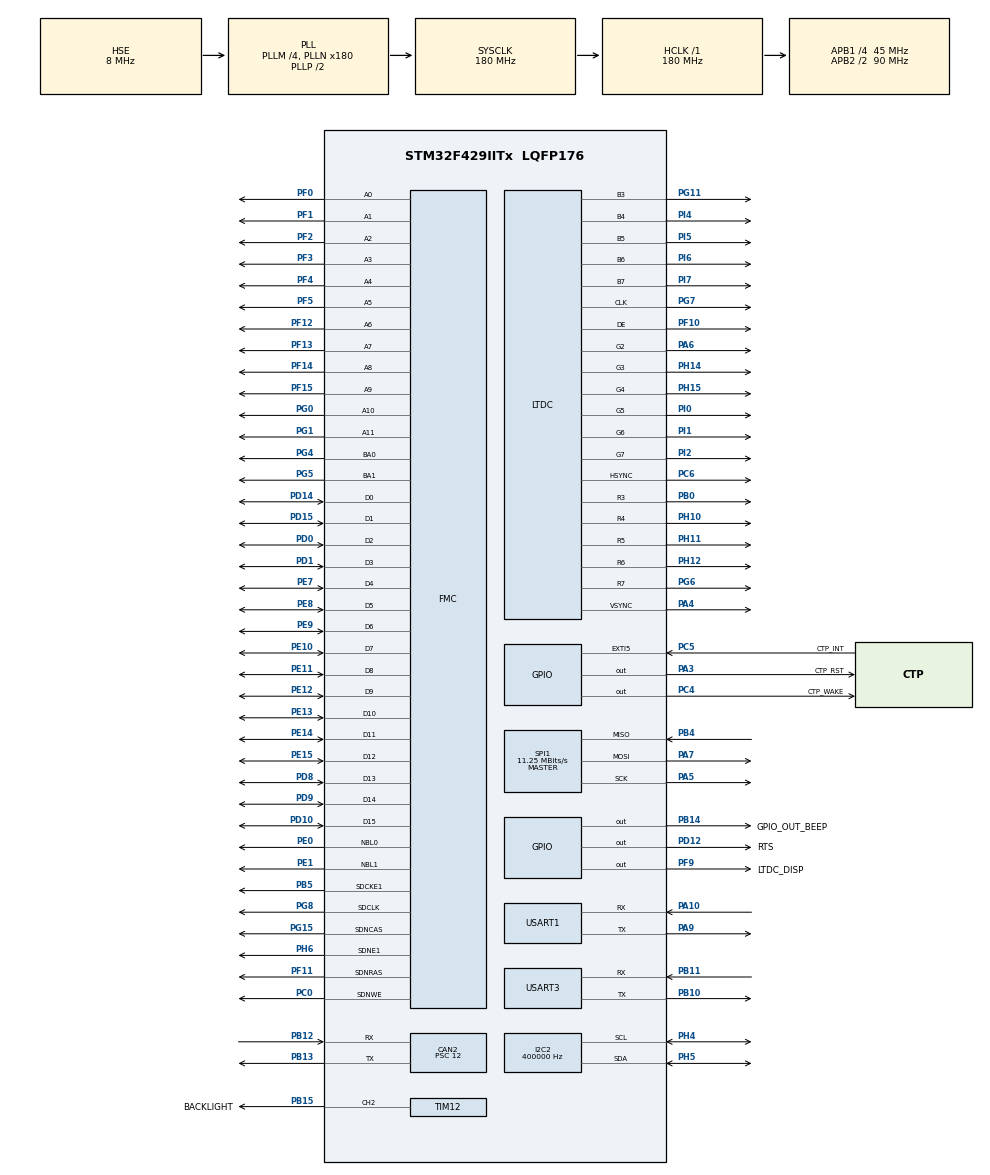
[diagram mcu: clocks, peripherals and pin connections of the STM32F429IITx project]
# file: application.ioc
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CAN2.ABOM=ENABLE
CAN2.BS1=CAN_BS1_12TQ
CAN2.BS2=CAN_BS2_2TQ
CAN2.CalculateBaudRate=250000
CAN2.CalculateTimeBit=3999.99
CAN2.CalculateTimeQuantum=266.66666666666663
CAN2.NART=ENABLE
CAN2.Prescaler=12
DMA2D.ColorMode=DMA2D_OUTPUT_RGB565
Dma.Request0=SPI1_RX
Dma.Request1=SPI1_TX
Dma.SPI1_RX.0.Direction=DMA_PERIPH_TO_MEMORY
Dma.SPI1_RX.0.FIFOMode=DMA_FIFOMODE_DISABLE
Dma.SPI1_RX.0.Instance=DMA2_Stream0
Dma.SPI1_RX.0.MemDataAlignment=DMA_MDATAALIGN_BYTE
Dma.SPI1_RX.0.MemInc=DMA_MINC_ENABLE
Dma.SPI1_RX.0.Mode=DMA_NORMAL
Dma.SPI1_RX.0.PeriphDataAlignment=DMA_PDATAALIGN_BYTE
Dma.SPI1_RX.0.PeriphInc=DMA_PINC_DISABLE
Dma.SPI1_RX.0.Priority=DMA_PRIORITY_LOW
Dma.SPI1_TX.1.Direction=DMA_MEMORY_TO_PERIPH
Dma.SPI1_TX.1.FIFOMode=DMA_FIFOMODE_DISABLE
Dma.SPI1_TX.1.Instance=DMA2_Stream3
Dma.SPI1_TX.1.MemDataAlignment=DMA_MDATAALIGN_BYTE
Dma.SPI1_TX.1.MemInc=DMA_MINC_ENABLE
Dma.SPI1_TX.1.Mode=DMA_NORMAL
Dma.SPI1_TX.1.PeriphDataAlignment=DMA_PDATAALIGN_BYTE
Dma.SPI1_TX.1.PeriphInc=DMA_PINC_DISABLE
Dma.SPI1_TX.1.Priority=DMA_PRIORITY_LOW
FMC.CASLatency2=FMC_SDRAM_CAS_LATENCY_3
FMC.ExitSelfRefreshDelay2=7
FMC.LoadToActiveDelay2=2
FMC.RCDDelay2=2
FMC.RPDelay1=2
FMC.RPDelay2=2
FMC.ReadBurst1=FMC_SDRAM_RBURST_ENABLE
FMC.ReadBurst2=FMC_SDRAM_RBURST_ENABLE
FMC.RowCycleDelay1=7
FMC.RowCycleDelay2=7
FMC.SDClockPeriod1=FMC_SDRAM_CLOCK_PERIOD_2
FMC.SDClockPeriod2=FMC_SDRAM_CLOCK_PERIOD_2
FMC.SelfRefreshTime2=4
FMC.WriteRecoveryTime2=3
FREERTOS.BinarySemaphores01=ModbusTaskBinarySem,Dynamic,NULL
FREERTOS.INCLUDE_uxTaskGetStackHighWaterMark=1
FREERTOS.INCLUDE_vTaskDelayUntil=1
FREERTOS.INCLUDE_xQueueGetMutexHolder=1
FREERTOS.Queues01=ObjectValueQueue,20,ReceiverData_t,0,Dynamic,NULL,NULL
FREERTOS.Tasks01=defaultTask,24,4096,StartDefaultTask,Default,NULL,Dynamic,NULL,NULL;ModbusRTUTask,24,512,StartModbusRTUTask,Default,NULL,Dynamic,NULL,NULL
FREERTOS.configTOTAL_HEAP_SIZE=40960
FREERTOS.configUSE_APPLICATION_TASK_TAG=1
FREERTOS.configUSE_DAEMON_TASK_STARTUP_HOOK=0
FREERTOS.configUSE_IDLE_HOOK=1
FREERTOS.configUSE_TICK_HOOK=1
I2C2.ClockSpeed=400000
I2C2.I2C_Mode=I2C_Fast
LTDC.ActiveW=800
LTDC.Alpha_L0=255
LTDC.FBStartAdress_L0=0xd0500000
LTDC.HFP=48
LTDC.ImageHeight_L0=480
LTDC.ImageWidth_L0=800
LTDC.Layers=0
LTDC.PixelFormat_L0=LTDC_PIXEL_FORMAT_RGB565
LTDC.VBP=12
LTDC.VFP=12
LTDC.VSync=8
LTDC.WindowX1_L0=800
LTDC.WindowY1_L0=480
Mcu.Family=STM32F4
Mcu.Name=STM32F429IITx
Mcu.Package=LQFP176
NVIC.CAN2_RX0_IRQn=true\:5\:0\:false\:false\:true\:true\:true\:true
NVIC.CAN2_RX1_IRQn=true\:5\:0\:false\:false\:true\:true\:true\:true
NVIC.DMA2D_IRQn=true\:5\:0\:true\:false\:true\:true\:true\:true
NVIC.DMA2_Stream0_IRQn=true\:5\:0\:false\:false\:true\:true\:false\:true
NVIC.DMA2_Stream3_IRQn=true\:5\:0\:false\:false\:true\:true\:false\:true
NVIC.I2C2_ER_IRQn=true\:5\:0\:false\:false\:true\:true\:true\:true
NVIC.I2C2_EV_IRQn=true\:5\:0\:false\:false\:true\:true\:true\:true
NVIC.LTDC_ER_IRQn=true\:5\:0\:true\:false\:true\:true\:true\:true
NVIC.LTDC_IRQn=true\:5\:0\:true\:false\:true\:true\:true\:true
NVIC.PriorityGroup=NVIC_PRIORITYGROUP_4
NVIC.TIM5_IRQn=true\:0\:0\:false\:false\:true\:false\:false\:true
NVIC.TIM7_IRQn=true\:5\:0\:false\:false\:true\:true\:true\:true
NVIC.TimeBase=TIM5_IRQn
NVIC.TimeBaseIP=TIM5
NVIC.USART1_IRQn=true\:5\:0\:false\:false\:true\:true\:true\:true
NVIC.USART3_IRQn=true\:5\:0\:false\:false\:true\:true\:true\:true
PA10.Mode=Asynchronous
PA10.Signal=USART1_RX
PA13.Mode=Serial_Wire
PA13.Signal=SYS_JTMS-SWDIO
PA14.Mode=Serial_Wire
PA14.Signal=SYS_JTCK-SWCLK
PA3.GPIO_Label=CTP_RST
PA3.Signal=GPIO_Output
PA4.Mode=RGB565
PA4.Signal=LTDC_VSYNC
PA5.Mode=Full_Duplex_Master
PA5.Signal=SPI1_SCK
PA6.Mode=RGB565
PA6.Signal=LTDC_G2
PA7.Mode=Full_Duplex_Master
PA7.Signal=SPI1_MOSI
PA9.Mode=Asynchronous
PA9.Signal=USART1_TX
PB0.Mode=RGB565
PB0.Signal=LTDC_R3
PB10.Mode=Asynchronous
PB10.Signal=USART3_TX
PB11.Mode=Asynchronous
PB11.Signal=USART3_RX
PB12.Mode=CAN_Activate
PB12.Signal=CAN2_RX
PB13.Mode=CAN_Activate
PB13.Signal=CAN2_TX
PB14.GPIO_Label=GPIO_OUT_BEEP
PB14.Signal=GPIO_Output
PB15.GPIO_Label=BACKLIGHT
PB15.Signal=S_TIM12_CH2
PB4.Mode=Full_Duplex_Master
PB4.Signal=SPI1_MISO
PB5.Mode=SdramChipSelect2_2
PB5.Signal=FMC_SDCKE1
PC0.Signal=FMC_SDNWE
PC14/OSC32_IN.Mode=LSE-External-Oscillator
PC14/OSC32_IN.Signal=RCC_OSC32_IN
PC15/OSC32_OUT.Mode=LSE-External-Oscillator
PC15/OSC32_OUT.Signal=RCC_OSC32_OUT
PC4.GPIO_Label=CTP_WAKE
PC4.Signal=GPIO_Output
PC5.GPIO_Label=CTP_INT
PC5.Signal=GPXTI5
PC6.Mode=RGB565
PC6.Signal=LTDC_HSYNC
PD0.Signal=FMC_D2_DA2
PD1.Signal=FMC_D3_DA3
PD10.Signal=FMC_D15_DA15
PD12.GPIO_Label=RTS
PD12.Signal=GPIO_Output
PD14.Signal=FMC_D0_DA0
PD15.Signal=FMC_D1_DA1
PD8.Signal=FMC_D13_DA13
PD9.Signal=FMC_D14_DA14
PE0.Signal=FMC_NBL0
PE1.Signal=FMC_NBL1
PE10.Signal=FMC_D7_DA7
PE11.Signal=FMC_D8_DA8
PE12.Signal=FMC_D9_DA9
PE13.Signal=FMC_D10_DA10
PE14.Signal=FMC_D11_DA11
PE15.Signal=FMC_D12_DA12
PE4.Signal=LTDC_B0
PE5.Signal=LTDC_G0
PE6.Signal=LTDC_G1
PE7.Signal=FMC_D4_DA4
PE8.Signal=FMC_D5_DA5
PE9.Signal=FMC_D6_DA6
PF0.Signal=FMC_A0
PF1.Signal=FMC_A1
PF10.Mode=RGB565
PF10.Signal=LTDC_DE
PF11.Signal=FMC_SDNRAS
PF12.Signal=FMC_A6
PF13.Signal=FMC_A7
PF14.Signal=FMC_A8
PF15.Signal=FMC_A9
PF2.Signal=FMC_A2
PF3.Signal=FMC_A3
PF4.Signal=FMC_A4
PF5.Signal=FMC_A5
PF9.GPIO_Label=LTDC_DISP
PF9.Signal=GPIO_Output
PG0.Signal=FMC_A10
PG1.Signal=FMC_A11
PG10.Signal=LTDC_B2
PG11.Mode=RGB565
PG11.Signal=LTDC_B3
PG12.Signal=LTDC_B1
PG15.Signal=FMC_SDNCAS
PG4.Signal=FMC_A14_BA0
PG5.Signal=FMC_A15_BA1
PG6.Mode=RGB565
PG6.Signal=LTDC_R7
PG7.Mode=RGB565
PG7.Signal=LTDC_CLK
PG8.Signal=FMC_SDCLK
PH0/OSC_IN.Mode=HSE-External-Oscillator
PH0/OSC_IN.Signal=RCC_OSC_IN
PH1/OSC_OUT.Mode=HSE-External-Oscillator
PH1/OSC_OUT.Signal=RCC_OSC_OUT
PH10.Mode=RGB565
PH10.Signal=LTDC_R4
PH11.Mode=RGB565
PH11.Signal=LTDC_R5
PH12.Mode=RGB565
PH12.Signal=LTDC_R6
PH14.Mode=RGB565
PH14.Signal=LTDC_G3
PH15.Mode=RGB565
PH15.Signal=LTDC_G4
PH4.Mode=I2C
PH4.Signal=I2C2_SCL
PH5.Mode=I2C
PH5.Signal=I2C2_SDA
PH6.Mode=SdramChipSelect2_2
PH6.Signal=FMC_SDNE1
PI0.Mode=RGB565
PI0.Signal=LTDC_G5
PI1.Mode=RGB565
PI1.Signal=LTDC_G6
PI2.Mode=RGB565
PI2.Signal=LTDC_G7
PI4.Mode=RGB565
PI4.Signal=LTDC_B4
PI5.Mode=RGB565
PI5.Signal=LTDC_B5
PI6.Mode=RGB565
PI6.Signal=LTDC_B6
PI7.Mode=RGB565
PI7.Signal=LTDC_B7
ProjectManager.HeapSize=0x1000
ProjectManager.StackSize=0x1000
ProjectManager.TargetToolchain=STM32CubeIDE
RCC.48MHZClocksFreq_Value=90000000
RCC.AHBFreq_Value=180000000
RCC.APB1CLKDivider=RCC_HCLK_DIV4
RCC.APB1Freq_Value=45000000
RCC.APB1TimFreq_Value=90000000
RCC.APB2CLKDivider=RCC_HCLK_DIV2
RCC.APB2Freq_Value=90000000
RCC.APB2TimFreq_Value=180000000
RCC.CortexFreq_Value=180000000
RCC.HCLKFreq_Value=180000000
RCC.HSE_VALUE=8000000
RCC.HSI_VALUE=16000000
RCC.LSE_Timout=1000
RCC.PLLM=4
RCC.PLLN=180
RCC.PLLSAIN=69
RCC.PLLSAIR=3
RCC.PLLSourceVirtual=RCC_PLLSOURCE_HSE
RCC.PWREXT_OverDrive=PWREXT_OverDrive_ACTIVATED
RCC.PWR_Regulator_Voltage_Scale=PWR_REGULATOR_VOLTAGE_SCALE1
RCC.RCC_RTC_Clock_Source=RCC_RTCCLKSOURCE_LSE
RCC.RCC_RTC_Clock_SourceVirtual=RCC_RTCCLKSOURCE_LSE
RCC.SYSCLKFreq_VALUE=180000000
RCC.SYSCLKSource=RCC_SYSCLKSOURCE_PLLCLK
RCC.VCOOutputFreq_Value=360000000
RTC.Format=RTC_FORMAT_BIN
RTC.Month=RTC_MONTH_JUNE
RTC.WeekDay=RTC_WEEKDAY_FRIDAY
RTC.Year=21
SH.FMC_A0.0=FMC_A0,12b-sda2
SH.FMC_A1.0=FMC_A1,12b-sda2
SH.FMC_A10.0=FMC_A10,12b-sda2
SH.FMC_A11.0=FMC_A11,12b-sda2
SH.FMC_A14_BA0.0=FMC_BA0,FourSdramBanks2
SH.FMC_A15_BA1.0=FMC_BA1,FourSdramBanks2
SH.FMC_A2.0=FMC_A2,12b-sda2
SH.FMC_A3.0=FMC_A3,12b-sda2
SH.FMC_A4.0=FMC_A4,12b-sda2
SH.FMC_A5.0=FMC_A5,12b-sda2
SH.FMC_A6.0=FMC_A6,12b-sda2
SH.FMC_A7.0=FMC_A7,12b-sda2
SH.FMC_A8.0=FMC_A8,12b-sda2
SH.FMC_A9.0=FMC_A9,12b-sda2
SH.FMC_D0_DA0.0=FMC_D0,sd-16b-d2
SH.FMC_D10_DA10.0=FMC_D10,sd-16b-d2
SH.FMC_D11_DA11.0=FMC_D11,sd-16b-d2
SH.FMC_D12_DA12.0=FMC_D12,sd-16b-d2
SH.FMC_D13_DA13.0=FMC_D13,sd-16b-d2
SH.FMC_D14_DA14.0=FMC_D14,sd-16b-d2
SH.FMC_D15_DA15.0=FMC_D15,sd-16b-d2
SH.FMC_D1_DA1.0=FMC_D1,sd-16b-d2
SH.FMC_D2_DA2.0=FMC_D2,sd-16b-d2
SH.FMC_D3_DA3.0=FMC_D3,sd-16b-d2
SH.FMC_D4_DA4.0=FMC_D4,sd-16b-d2
SH.FMC_D5_DA5.0=FMC_D5,sd-16b-d2
SH.FMC_D6_DA6.0=FMC_D6,sd-16b-d2
SH.FMC_D7_DA7.0=FMC_D7,sd-16b-d2
SH.FMC_D8_DA8.0=FMC_D8,sd-16b-d2
SH.FMC_D9_DA9.0=FMC_D9,sd-16b-d2
SH.FMC_NBL0.0=FMC_NBL0,Sd2ByteEnable2
SH.FMC_NBL1.0=FMC_NBL1,Sd2ByteEnable2
SH.FMC_SDCLK.0=FMC_SDCLK,12b-sda2
SH.FMC_SDNCAS.0=FMC_SDNCAS,12b-sda2
SH.FMC_SDNRAS.0=FMC_SDNRAS,12b-sda2
SH.FMC_SDNWE.0=FMC_SDNWE,12b-sda2
SH.S_TIM12_CH2.0=TIM12_CH2,PWM Generation2 CH2
SPI1.BaudRatePrescaler=SPI_BAUDRATEPRESCALER_8
SPI1.CalculateBaudRate=11.25 MBits/s
SPI1.Direction=SPI_DIRECTION_2LINES
SPI1.Mode=SPI_MODE_MASTER
SPI1.VirtualType=VM_MASTER
STMicroelectronics.X-CUBE-TOUCHGFX.4.16.1.ApplicationCcGraphicsJjApplication=TouchGFXOoGenerator
STMicroelectronics.X-CUBE-TOUCHGFX.4.16.1.tgfx_address1=0xd0500000
STMicroelectronics.X-CUBE-TOUCHGFX.4.16.1.tgfx_address2=0xd05bb800
STMicroelectronics.X-CUBE-TOUCHGFX.4.16.1.tgfx_buffering_strategy=Double
STMicroelectronics.X-CUBE-TOUCHGFX.4.16.1.tgfx_custom_height=480
STMicroelectronics.X-CUBE-TOUCHGFX.4.16.1.tgfx_display_interface=disp_ltdc
STMicroelectronics.X-CUBE-TOUCHGFX.4.16.1.tgfx_hardware_accelerator=dma_2d
STMicroelectronics.X-CUBE-TOUCHGFX.4.16.1.tgfx_location=By Address
STMicroelectronics.X-CUBE-TOUCHGFX.4.16.1.tgfx_vsync=vsync_ltdc
TIM10.Period=0
TIM12.Channel-PWM\ Generation2\ CH2=TIM_CHANNEL_2
TIM12.Period=99
TIM12.Prescaler=450-1
TIM7.Period=0
USART1.VirtualMode=VM_ASYNC
USART3.VirtualMode=VM_ASYNC
VP_CRC_VS_CRC.Mode=CRC_Activate
VP_DMA2D_VS_DMA2D.Mode=DMA2D_Activate
VP_FREERTOS_VS_CMSIS_V2.Mode=CMSIS_V2
VP_RTC_VS_RTC_Activate.Mode=RTC_Enabled
VP_RTC_VS_RTC_Calendar.Mode=RTC_Calendar
VP_STMicroelectronics.X-CUBE-TOUCHGFX_VS_GraphicsJjApplication_4.16.1.Mode=GraphicsJjApplication
VP_SYS_VS_tim5.Mode=TIM5
VP_TIM10_VS_ClockSourceINT.Mode=Enable_Timer
VP_TIM12_VS_ClockSourceINT.Mode=Internal
VP_TIM7_VS_ClockSourceINT.Mode=Enable_Timer
board=custom

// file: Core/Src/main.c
/* USER CODE BEGIN Header */
/**
  ******************************************************************************
  * @file           : main.c
  * @brief          : Main program body
  ******************************************************************************
  * @attention
  *
  * <h2><center>&copy; Copyright (c) 2022 STMicroelectronics.
  * All rights reserved.</center></h2>
  *
  * This software component is licensed by ST under Ultimate Liberty license
  * SLA0044, the "License"; You may not use this file except in compliance with
  * the License. You may obtain a copy of the License at:
  *                             www.st.com/SLA0044
  *
  ******************************************************************************
  */
/* USER CODE END Header */
#include "main.h"
#include "cmsis_os.h"
#include "app_touchgfx.h"

/* USER CODE BEGIN Includes */
#include <string.h>
#include <stdio.h>
#include "ExHardware.h"
#include "w25q128jv.h"
/* USER CODE END Includes */

CAN_HandleTypeDef hcan2;

CRC_HandleTypeDef hcrc;

DMA2D_HandleTypeDef hdma2d;

I2C_HandleTypeDef hi2c2;

LTDC_HandleTypeDef hltdc;

RTC_HandleTypeDef hrtc;

SPI_HandleTypeDef hspi1;
DMA_HandleTypeDef hdma_spi1_rx;
DMA_HandleTypeDef hdma_spi1_tx;

TIM_HandleTypeDef htim7;
TIM_HandleTypeDef htim10;
TIM_HandleTypeDef htim12;

UART_HandleTypeDef huart1;
UART_HandleTypeDef huart3;

SDRAM_HandleTypeDef hsdram2;

/* Definitions for defaultTask */
osThreadId_t defaultTaskHandle;
const osThreadAttr_t defaultTask_attributes = {
  .name = "defaultTask",
  .stack_size = 4096 * 4,
  .priority = (osPriority_t) osPriorityNormal,
};
/* Definitions for ModbusRTUTask */
osThreadId_t ModbusRTUTaskHandle;
const osThreadAttr_t ModbusRTUTask_attributes = {
  .name = "ModbusRTUTask",
  .stack_size = 512 * 4,
  .priority = (osPriority_t) osPriorityNormal,
};
/* Definitions for ObjectValueQueue */
osMessageQueueId_t ObjectValueQueueHandle;
const osMessageQueueAttr_t ObjectValueQueue_attributes = {
  .name = "ObjectValueQueue"
};
/* Definitions for ModbusTaskBinarySem */
osSemaphoreId_t ModbusTaskBinarySemHandle;
const osSemaphoreAttr_t ModbusTaskBinarySem_attributes = {
  .name = "ModbusTaskBinarySem"
};
/* USER CODE BEGIN PV */
uint8_t cacheBuf[ CACHE_SIZE ] __attribute__ ((section (".sdram.CatchBuffer")));
/* USER CODE END PV */

void SystemClock_Config(void);
static void MX_GPIO_Init(void);
static void MX_DMA_Init(void);
static void MX_CAN2_Init(void);
static void MX_LTDC_Init(void);
static void MX_FMC_Init(void);
static void MX_TIM7_Init(void);
static void MX_TIM10_Init(void);
static void MX_TIM12_Init(void);
static void MX_I2C2_Init(void);
static void MX_SPI1_Init(void);
static void MX_DMA2D_Init(void);
static void MX_USART1_UART_Init(void);
static void MX_USART3_UART_Init(void);
static void MX_CRC_Init(void);
static void MX_RTC_Init(void);
void StartDefaultTask(void *argument);
void StartModbusRTUTask(void *argument);

/* USER CODE BEGIN PFP */
void MX_SDRAM_InitEx ( void );
void ModbusRTUProcess ( void );
/* USER CODE END PFP */

int main(void)
{

  /* MCU Configuration--------------------------------------------------------*/

  /* Reset of all peripherals, Initializes the Flash interface and the Systick. */
  HAL_Init();

  /* Configure the system clock */
  SystemClock_Config();

  /* Initialize all configured peripherals */
  MX_GPIO_Init();
  MX_DMA_Init();
  MX_CAN2_Init();
  MX_LTDC_Init();
  MX_FMC_Init();
  MX_TIM7_Init();
  MX_TIM10_Init();
  MX_TIM12_Init();
  MX_I2C2_Init();
  MX_SPI1_Init();
  MX_DMA2D_Init();
  MX_USART1_UART_Init();
  MX_USART3_UART_Init();
  MX_CRC_Init();
  MX_RTC_Init();
  MX_TouchGFX_Init();
  /* USER CODE BEGIN 2 */
  *brightness = 100;
  Backlight_Control( BL_ON );
  /* USER CODE END 2 */

  /* Init scheduler */
  osKernelInitialize();

  /* Create the semaphores(s) */
  /* creation of ModbusTaskBinarySem */
  ModbusTaskBinarySemHandle = osSemaphoreNew(1, 1, &ModbusTaskBinarySem_attributes);

  /* Create the queue(s) */
  /* creation of ObjectValueQueue */
  ObjectValueQueueHandle = osMessageQueueNew (20, sizeof(ReceiverData_t), &ObjectValueQueue_attributes);

  /* Create the thread(s) */
  /* creation of defaultTask */
  defaultTaskHandle = osThreadNew(StartDefaultTask, NULL, &defaultTask_attributes);

  /* creation of ModbusRTUTask */
  ModbusRTUTaskHandle = osThreadNew(StartModbusRTUTask, NULL, &ModbusRTUTask_attributes);

  /* Start scheduler */
  osKernelStart();

  /* We should never get here as control is now taken by the scheduler */
  /* Infinite loop */
  while (1)
  {

  }
}

void SystemClock_Config(void)
{
	int CHECKLSI = 0;
  RCC_OscInitTypeDef RCC_OscInitStruct = {0};
  RCC_ClkInitTypeDef RCC_ClkInitStruct = {0};
  RCC_PeriphCLKInitTypeDef PeriphClkInitStruct = {0};

  /** Configure the main internal regulator output voltage
  */
  LSI:
  __HAL_RCC_PWR_CLK_ENABLE();
  __HAL_PWR_VOLTAGESCALING_CONFIG(PWR_REGULATOR_VOLTAGE_SCALE1);
  /** Initializes the RCC Oscillators according to the specified parameters
  * in the RCC_OscInitTypeDef structure.
  */
  if(CHECKLSI == 0)
  {
	  RCC_OscInitStruct.OscillatorType = RCC_OSCILLATORTYPE_HSE|RCC_OSCILLATORTYPE_LSE;
	  RCC_OscInitStruct.HSEState = RCC_HSE_ON;
	  RCC_OscInitStruct.LSEState = RCC_LSE_ON;
	  RCC_OscInitStruct.PLL.PLLState = RCC_PLL_ON;
	  RCC_OscInitStruct.PLL.PLLSource = RCC_PLLSOURCE_HSE;
	  RCC_OscInitStruct.PLL.PLLM = 4;
	  RCC_OscInitStruct.PLL.PLLN = 180;
	  RCC_OscInitStruct.PLL.PLLP = RCC_PLLP_DIV2;
	  RCC_OscInitStruct.PLL.PLLQ = 4;
  }
  else
  {
	  RCC_OscInitStruct.OscillatorType = RCC_OSCILLATORTYPE_LSI|RCC_OSCILLATORTYPE_HSE;
	  RCC_OscInitStruct.HSEState = RCC_HSE_ON;
	  RCC_OscInitStruct.LSIState =  RCC_LSI_ON;;
	  RCC_OscInitStruct.PLL.PLLState = RCC_PLL_ON;
	  RCC_OscInitStruct.PLL.PLLSource = RCC_PLLSOURCE_HSE;
	  RCC_OscInitStruct.PLL.PLLM = 4;
	  RCC_OscInitStruct.PLL.PLLN = 180;
	  RCC_OscInitStruct.PLL.PLLP = RCC_PLLP_DIV2;
	  RCC_OscInitStruct.PLL.PLLQ = 4;
  }

  if (HAL_RCC_OscConfig(&RCC_OscInitStruct) != HAL_OK)
  {
    CHECKLSI = 1;
    goto LSI;
    Error_Handler();
  }
  /** Activate the Over-Drive mode
  */
  if (HAL_PWREx_EnableOverDrive() != HAL_OK)
  {
    Error_Handler();
  }
  /** Initializes the CPU, AHB and APB buses clocks
  */
  RCC_ClkInitStruct.ClockType = RCC_CLOCKTYPE_HCLK|RCC_CLOCKTYPE_SYSCLK
                              |RCC_CLOCKTYPE_PCLK1|RCC_CLOCKTYPE_PCLK2;
  RCC_ClkInitStruct.SYSCLKSource = RCC_SYSCLKSOURCE_PLLCLK;
  RCC_ClkInitStruct.AHBCLKDivider = RCC_SYSCLK_DIV1;
  RCC_ClkInitStruct.APB1CLKDivider = RCC_HCLK_DIV4;
  RCC_ClkInitStruct.APB2CLKDivider = RCC_HCLK_DIV2;

  if (HAL_RCC_ClockConfig(&RCC_ClkInitStruct, FLASH_LATENCY_5) != HAL_OK)
  {
    Error_Handler();
  }
  PeriphClkInitStruct.PeriphClockSelection = RCC_PERIPHCLK_LTDC|RCC_PERIPHCLK_RTC;
  PeriphClkInitStruct.PLLSAI.PLLSAIN = 69;
  PeriphClkInitStruct.PLLSAI.PLLSAIR = 3;
  PeriphClkInitStruct.PLLSAIDivR = RCC_PLLSAIDIVR_2;
  if(CHECKLSI == 1)
	  PeriphClkInitStruct.RTCClockSelection = RCC_RTCCLKSOURCE_LSI;
  else
	  PeriphClkInitStruct.RTCClockSelection = RCC_RTCCLKSOURCE_LSE;
  if (HAL_RCCEx_PeriphCLKConfig(&PeriphClkInitStruct) != HAL_OK)
  {
	  goto LSI;
    Error_Handler();
  }
}

static void MX_CAN2_Init(void)
{

  hcan2.Instance = CAN2;
  hcan2.Init.Prescaler = 12;
  hcan2.Init.Mode = CAN_MODE_NORMAL;
  hcan2.Init.SyncJumpWidth = CAN_SJW_1TQ;
  hcan2.Init.TimeSeg1 = CAN_BS1_12TQ;
  hcan2.Init.TimeSeg2 = CAN_BS2_2TQ;
  hcan2.Init.TimeTriggeredMode = DISABLE;
  hcan2.Init.AutoBusOff = ENABLE;
  hcan2.Init.AutoWakeUp = DISABLE;
  hcan2.Init.AutoRetransmission = ENABLE;
  hcan2.Init.ReceiveFifoLocked = DISABLE;
  hcan2.Init.TransmitFifoPriority = DISABLE;
  if (HAL_CAN_Init(&hcan2) != HAL_OK)
  {
    Error_Handler();
  }
  /* USER CODE BEGIN CAN2_Init 2 */
  CAN_FilterTypeDef  sFilterConfig;

  /*##-2- Configure the CAN Filter ###########################################*/
  sFilterConfig.FilterBank = 14;
  sFilterConfig.FilterMode = CAN_FILTERMODE_IDMASK;
  sFilterConfig.FilterScale = CAN_FILTERSCALE_32BIT;
  sFilterConfig.FilterIdHigh = 0x0000;
  sFilterConfig.FilterIdLow = 0x0000;
  sFilterConfig.FilterMaskIdHigh = 0x0000;
  sFilterConfig.FilterMaskIdLow = 0x0000;
  sFilterConfig.FilterFIFOAssignment = CAN_RX_FIFO0;
  sFilterConfig.FilterActivation = ENABLE;
  sFilterConfig.SlaveStartFilterBank = 14;

  if ( HAL_CAN_ConfigFilter( &hcan2, &sFilterConfig ) != HAL_OK) {
	  return;
      /* Filter configuration Error */
      Error_Handler();
  }
  sFilterConfig.FilterFIFOAssignment = CAN_RX_FIFO1;

  if ( HAL_CAN_ConfigFilter( &hcan2, &sFilterConfig ) != HAL_OK) {
	  return;
      /* Filter configuration Error */
      Error_Handler();
  }

//  HAL_CAN_RegisterCallback(&hcan2, HAL_CAN_RX_FIFO0_MSG_PENDING_CB_ID, CustomCAN_RxFifoMsgPendingCallback );
//  HAL_CAN_RegisterCallback(&hcan2, HAL_CAN_RX_FIFO1_MSG_PENDING_CB_ID, CustomCAN_RxFifoMsgPendingCallback );

  /*##-3- Start the CAN peripheral ###########################################*/
  if( HAL_CAN_Start( &hcan2 ) != HAL_OK ) {
	  return;
      /* Start Error */
      Error_Handler( );
  }

  /*##-4- Activate CAN RX notification #######################################*/
  if( HAL_CAN_ActivateNotification( &hcan2, CAN_IT_RX_FIFO0_MSG_PENDING ) != HAL_OK) {
	  return;
      /* Notification Error */
      Error_Handler();
  }

  if( HAL_CAN_ActivateNotification( &hcan2, CAN_IT_RX_FIFO1_MSG_PENDING ) != HAL_OK) {
	  return;
	  /* Notification Error */
      Error_Handler();
  }

  if( HAL_CAN_ActivateNotification( &hcan2, CAN_IT_TX_MAILBOX_EMPTY	) != HAL_OK) {
      /* Notification Error */
      Error_Handler();
  }
  /* USER CODE END CAN2_Init 2 */

}

static void MX_CRC_Init(void)
{

  hcrc.Instance = CRC;
  if (HAL_CRC_Init(&hcrc) != HAL_OK)
  {
    Error_Handler();
  }

}

static void MX_DMA2D_Init(void)
{

  hdma2d.Instance = DMA2D;
  hdma2d.Init.Mode = DMA2D_M2M;
  hdma2d.Init.ColorMode = DMA2D_OUTPUT_RGB565;
  hdma2d.Init.OutputOffset = 0;
  hdma2d.LayerCfg[1].InputOffset = 0;
  hdma2d.LayerCfg[1].InputColorMode = DMA2D_INPUT_RGB565;
  hdma2d.LayerCfg[1].AlphaMode = DMA2D_NO_MODIF_ALPHA;
  hdma2d.LayerCfg[1].InputAlpha = 0;
  if (HAL_DMA2D_Init(&hdma2d) != HAL_OK)
  {
    Error_Handler();
  }
  if (HAL_DMA2D_ConfigLayer(&hdma2d, 1) != HAL_OK)
  {
    Error_Handler();
  }

}

static void MX_I2C2_Init(void)
{

  hi2c2.Instance = I2C2;
  hi2c2.Init.ClockSpeed = 400000;
  hi2c2.Init.DutyCycle = I2C_DUTYCYCLE_2;
  hi2c2.Init.OwnAddress1 = 0;
  hi2c2.Init.AddressingMode = I2C_ADDRESSINGMODE_7BIT;
  hi2c2.Init.DualAddressMode = I2C_DUALADDRESS_DISABLE;
  hi2c2.Init.OwnAddress2 = 0;
  hi2c2.Init.GeneralCallMode = I2C_GENERALCALL_DISABLE;
  hi2c2.Init.NoStretchMode = I2C_NOSTRETCH_DISABLE;
  if (HAL_I2C_Init(&hi2c2) != HAL_OK)
  {
    Error_Handler();
  }
  /** Configure Analogue filter
  */
  if (HAL_I2CEx_ConfigAnalogFilter(&hi2c2, I2C_ANALOGFILTER_ENABLE) != HAL_OK)
  {
    Error_Handler();
  }
  /** Configure Digital filter
  */
  if (HAL_I2CEx_ConfigDigitalFilter(&hi2c2, 0) != HAL_OK)
  {
    Error_Handler();
  }

}

static void MX_LTDC_Init(void)
{

  /* USER CODE BEGIN LTDC_Init 0 */
	hltdc.Instance = LTDC;
	HAL_LTDC_DeInit(&hltdc);
  /* USER CODE END LTDC_Init 0 */

  LTDC_LayerCfgTypeDef pLayerCfg = {0};

  hltdc.Instance = LTDC;
  hltdc.Init.HSPolarity = LTDC_HSPOLARITY_AL;
  hltdc.Init.VSPolarity = LTDC_VSPOLARITY_AL;
  hltdc.Init.DEPolarity = LTDC_DEPOLARITY_AL;
  hltdc.Init.PCPolarity = LTDC_PCPOLARITY_IPC;
  hltdc.Init.HorizontalSync = 7;
  hltdc.Init.VerticalSync = 7;
  hltdc.Init.AccumulatedHBP = 14;
  hltdc.Init.AccumulatedVBP = 19;
  hltdc.Init.AccumulatedActiveW = 814;
  hltdc.Init.AccumulatedActiveH = 499;
  hltdc.Init.TotalWidth = 862;
  hltdc.Init.TotalHeigh = 511;
  hltdc.Init.Backcolor.Blue = 0;
  hltdc.Init.Backcolor.Green = 0;
  hltdc.Init.Backcolor.Red = 0;
  if (HAL_LTDC_Init(&hltdc) != HAL_OK)
  {
    Error_Handler();
  }
  pLayerCfg.WindowX0 = 0;
  pLayerCfg.WindowX1 = 800;
  pLayerCfg.WindowY0 = 0;
  pLayerCfg.WindowY1 = 480;
  pLayerCfg.PixelFormat = LTDC_PIXEL_FORMAT_RGB565;
  pLayerCfg.Alpha = 255;
  pLayerCfg.Alpha0 = 0;
  pLayerCfg.BlendingFactor1 = LTDC_BLENDING_FACTOR1_CA;
  pLayerCfg.BlendingFactor2 = LTDC_BLENDING_FACTOR2_CA;
  pLayerCfg.FBStartAdress = 0xd0500000;
  pLayerCfg.ImageWidth = 800;
  pLayerCfg.ImageHeight = 480;
  pLayerCfg.Backcolor.Blue = 0;
  pLayerCfg.Backcolor.Green = 0;
  pLayerCfg.Backcolor.Red = 0;
  if (HAL_LTDC_ConfigLayer(&hltdc, &pLayerCfg, 0) != HAL_OK)
  {
    Error_Handler();
  }
  /* USER CODE BEGIN LTDC_Init 2 */
  HAL_LTDC_SetPitch(&hltdc, 800, 0);

   HAL_GPIO_WritePin(LTDC_DISP_GPIO_Port, LTDC_DISP_Pin, GPIO_PIN_RESET);

   	HAL_Delay( 100 );

   	HAL_GPIO_WritePin(LTDC_DISP_GPIO_Port, LTDC_DISP_Pin, GPIO_PIN_SET);

   	HAL_Delay( 20 );
  /* USER CODE END LTDC_Init 2 */

}

static void MX_RTC_Init(void)
{

  RTC_TimeTypeDef sTime = {0};
  RTC_DateTypeDef sDate = {0};

  /** Initialize RTC Only
  */
  hrtc.Instance = RTC;
  hrtc.Init.HourFormat = RTC_HOURFORMAT_24;
  hrtc.Init.AsynchPrediv = 127;
  hrtc.Init.SynchPrediv = 255;
  hrtc.Init.OutPut = RTC_OUTPUT_DISABLE;
  hrtc.Init.OutPutPolarity = RTC_OUTPUT_POLARITY_HIGH;
  hrtc.Init.OutPutType = RTC_OUTPUT_TYPE_OPENDRAIN;
  if (HAL_RTC_Init(&hrtc) != HAL_OK)
  {
    Error_Handler();
  }

  /** Initialize RTC and set the Time and Date
  */
  sTime.Hours = 0;
  sTime.Minutes = 0;
  sTime.Seconds = 0;
  sTime.DayLightSaving = RTC_DAYLIGHTSAVING_NONE;
  sTime.StoreOperation = RTC_STOREOPERATION_RESET;
  if (HAL_RTC_SetTime(&hrtc, &sTime, RTC_FORMAT_BIN) != HAL_OK)
  {
    Error_Handler();
  }
  sDate.WeekDay = RTC_WEEKDAY_FRIDAY;
  sDate.Month = RTC_MONTH_JUNE;
  sDate.Date = 1;
  sDate.Year = 21;

  if (HAL_RTC_SetDate(&hrtc, &sDate, RTC_FORMAT_BIN) != HAL_OK)
  {
    Error_Handler();
  }

}

static void MX_SPI1_Init(void)
{

  /* USER CODE BEGIN SPI1_Init 0 */
	  hspi1.Instance = SPI1;
	  HAL_SPI_DeInit(&hspi1);
  /* USER CODE END SPI1_Init 0 */

  /* SPI1 parameter configuration*/
  hspi1.Instance = SPI1;
  hspi1.Init.Mode = SPI_MODE_MASTER;
  hspi1.Init.Direction = SPI_DIRECTION_2LINES;
  hspi1.Init.DataSize = SPI_DATASIZE_8BIT;
  hspi1.Init.CLKPolarity = SPI_POLARITY_LOW;
  hspi1.Init.CLKPhase = SPI_PHASE_1EDGE;
  hspi1.Init.NSS = SPI_NSS_SOFT;
  hspi1.Init.BaudRatePrescaler = SPI_BAUDRATEPRESCALER_8;
  hspi1.Init.FirstBit = SPI_FIRSTBIT_MSB;
  hspi1.Init.TIMode = SPI_TIMODE_DISABLE;
  hspi1.Init.CRCCalculation = SPI_CRCCALCULATION_DISABLE;
  hspi1.Init.CRCPolynomial = 10;
  if (HAL_SPI_Init(&hspi1) != HAL_OK)
  {
    Error_Handler();
  }
  /* USER CODE BEGIN SPI1_Init 2 */
  Inital_SPI_Flash();
  /* USER CODE END SPI1_Init 2 */

}

static void MX_TIM7_Init(void)
{

  TIM_MasterConfigTypeDef sMasterConfig = {0};

  htim7.Instance = TIM7;
  htim7.Init.Prescaler = 0;
  htim7.Init.CounterMode = TIM_COUNTERMODE_UP;
  htim7.Init.Period = 0;
  htim7.Init.AutoReloadPreload = TIM_AUTORELOAD_PRELOAD_DISABLE;
  if (HAL_TIM_Base_Init(&htim7) != HAL_OK)
  {
    Error_Handler();
  }
  sMasterConfig.MasterOutputTrigger = TIM_TRGO_RESET;
  sMasterConfig.MasterSlaveMode = TIM_MASTERSLAVEMODE_DISABLE;
  if (HAL_TIMEx_MasterConfigSynchronization(&htim7, &sMasterConfig) != HAL_OK)
  {
    Error_Handler();
  }

}

static void MX_TIM10_Init(void)
{

  htim10.Instance = TIM10;
  htim10.Init.Prescaler = 0;
  htim10.Init.CounterMode = TIM_COUNTERMODE_UP;
  htim10.Init.Period = 0;
  htim10.Init.ClockDivision = TIM_CLOCKDIVISION_DIV1;
  htim10.Init.AutoReloadPreload = TIM_AUTORELOAD_PRELOAD_DISABLE;
  if (HAL_TIM_Base_Init(&htim10) != HAL_OK)
  {
    Error_Handler();
  }

}

static void MX_TIM12_Init(void)
{

  TIM_ClockConfigTypeDef sClockSourceConfig = {0};
  TIM_OC_InitTypeDef sConfigOC = {0};

  htim12.Instance = TIM12;
  htim12.Init.Prescaler = 450-1;
  htim12.Init.CounterMode = TIM_COUNTERMODE_UP;
  htim12.Init.Period = 99;
  htim12.Init.ClockDivision = TIM_CLOCKDIVISION_DIV1;
  htim12.Init.AutoReloadPreload = TIM_AUTORELOAD_PRELOAD_DISABLE;
  if (HAL_TIM_Base_Init(&htim12) != HAL_OK)
  {
    Error_Handler();
  }
  sClockSourceConfig.ClockSource = TIM_CLOCKSOURCE_INTERNAL;
  if (HAL_TIM_ConfigClockSource(&htim12, &sClockSourceConfig) != HAL_OK)
  {
    Error_Handler();
  }
  if (HAL_TIM_PWM_Init(&htim12) != HAL_OK)
  {
    Error_Handler();
  }
  sConfigOC.OCMode = TIM_OCMODE_PWM1;
  sConfigOC.Pulse = 0;
  sConfigOC.OCPolarity = TIM_OCPOLARITY_HIGH;
  sConfigOC.OCFastMode = TIM_OCFAST_DISABLE;
  if (HAL_TIM_PWM_ConfigChannel(&htim12, &sConfigOC, TIM_CHANNEL_2) != HAL_OK)
  {
    Error_Handler();
  }
  HAL_TIM_MspPostInit(&htim12);

}

static void MX_USART1_UART_Init(void)
{

  huart1.Instance = USART1;
  huart1.Init.BaudRate = 115200;
  huart1.Init.WordLength = UART_WORDLENGTH_8B;
  huart1.Init.StopBits = UART_STOPBITS_1;
  huart1.Init.Parity = UART_PARITY_NONE;
  huart1.Init.Mode = UART_MODE_TX_RX;
  huart1.Init.HwFlowCtl = UART_HWCONTROL_NONE;
  huart1.Init.OverSampling = UART_OVERSAMPLING_16;
  if (HAL_UART_Init(&huart1) != HAL_OK)
  {
    Error_Handler();
  }
  /* USER CODE BEGIN USART1_Init 2 */
  __HAL_UART_ENABLE_IT( &huart1, UART_IT_ERR );
  /* USER CODE END USART1_Init 2 */

}

static void MX_USART3_UART_Init(void)
{

  huart3.Instance = USART3;
  huart3.Init.BaudRate = 115200;
  huart3.Init.WordLength = UART_WORDLENGTH_8B;
  huart3.Init.StopBits = UART_STOPBITS_1;
  huart3.Init.Parity = UART_PARITY_NONE;
  huart3.Init.Mode = UART_MODE_TX_RX;
  huart3.Init.HwFlowCtl = UART_HWCONTROL_NONE;
  huart3.Init.OverSampling = UART_OVERSAMPLING_16;
  if (HAL_UART_Init(&huart3) != HAL_OK)
  {
    Error_Handler();
  }
  /* USER CODE BEGIN USART3_Init 2 */
//  __HAL_UART_ENABLE_IT( &huart3, UART_IT_ERR );
  /* USER CODE END USART3_Init 2 */

}

static void MX_DMA_Init(void)
{

  /* DMA controller clock enable */
  __HAL_RCC_DMA2_CLK_ENABLE();

  /* DMA interrupt init */
  /* DMA2_Stream0_IRQn interrupt configuration */
  HAL_NVIC_SetPriority(DMA2_Stream0_IRQn, 5, 0);
  HAL_NVIC_EnableIRQ(DMA2_Stream0_IRQn);
  /* DMA2_Stream3_IRQn interrupt configuration */
  HAL_NVIC_SetPriority(DMA2_Stream3_IRQn, 5, 0);
  HAL_NVIC_EnableIRQ(DMA2_Stream3_IRQn);

}

/* FMC initialization function */
static void MX_FMC_Init(void)
{

  FMC_SDRAM_TimingTypeDef SdramTiming = {0};

  /** Perform the SDRAM2 memory initialization sequence
  */
  hsdram2.Instance = FMC_SDRAM_DEVICE;
  /* hsdram2.Init */
  hsdram2.Init.SDBank = FMC_SDRAM_BANK2;
  hsdram2.Init.ColumnBitsNumber = FMC_SDRAM_COLUMN_BITS_NUM_8;
  hsdram2.Init.RowBitsNumber = FMC_SDRAM_ROW_BITS_NUM_12;
  hsdram2.Init.MemoryDataWidth = FMC_SDRAM_MEM_BUS_WIDTH_16;
  hsdram2.Init.InternalBankNumber = FMC_SDRAM_INTERN_BANKS_NUM_4;
  hsdram2.Init.CASLatency = FMC_SDRAM_CAS_LATENCY_3;
  hsdram2.Init.WriteProtection = FMC_SDRAM_WRITE_PROTECTION_DISABLE;
  hsdram2.Init.SDClockPeriod = FMC_SDRAM_CLOCK_PERIOD_2;
  hsdram2.Init.ReadBurst = FMC_SDRAM_RBURST_ENABLE;
  hsdram2.Init.ReadPipeDelay = FMC_SDRAM_RPIPE_DELAY_0;
  /* SdramTiming */
  SdramTiming.LoadToActiveDelay = 2;
  SdramTiming.ExitSelfRefreshDelay = 7;
  SdramTiming.SelfRefreshTime = 4;
  SdramTiming.RowCycleDelay = 7;
  SdramTiming.WriteRecoveryTime = 3;
  SdramTiming.RPDelay = 2;
  SdramTiming.RCDDelay = 2;

  if (HAL_SDRAM_Init(&hsdram2, &SdramTiming) != HAL_OK)
  {
    Error_Handler( );
  }

  /* USER CODE BEGIN FMC_Init 2 */
  MX_SDRAM_InitEx( );
  memset((void *) 0xd0500000, 0, 800 * 480 * 4);
  /* USER CODE END FMC_Init 2 */
}

static void MX_GPIO_Init(void)
{
  GPIO_InitTypeDef GPIO_InitStruct = {0};

  /* GPIO Ports Clock Enable */
  __HAL_RCC_GPIOE_CLK_ENABLE();
  __HAL_RCC_GPIOC_CLK_ENABLE();
  __HAL_RCC_GPIOF_CLK_ENABLE();
  __HAL_RCC_GPIOH_CLK_ENABLE();
  __HAL_RCC_GPIOA_CLK_ENABLE();
  __HAL_RCC_GPIOB_CLK_ENABLE();
  __HAL_RCC_GPIOG_CLK_ENABLE();
  __HAL_RCC_GPIOD_CLK_ENABLE();
  __HAL_RCC_GPIOI_CLK_ENABLE();

  /*Configure GPIO pin Output Level */
  HAL_GPIO_WritePin(LTDC_DISP_GPIO_Port, LTDC_DISP_Pin, GPIO_PIN_RESET);

  /*Configure GPIO pin Output Level */
  HAL_GPIO_WritePin(CTP_RST_GPIO_Port, CTP_RST_Pin, GPIO_PIN_RESET);

  /*Configure GPIO pin Output Level */
  HAL_GPIO_WritePin(CTP_WAKE_GPIO_Port, CTP_WAKE_Pin, GPIO_PIN_RESET);

  /*Configure GPIO pin Output Level */
  HAL_GPIO_WritePin(GPIO_OUT_BEEP_GPIO_Port, GPIO_OUT_BEEP_Pin, GPIO_PIN_RESET);

  /*Configure GPIO pin Output Level */
  HAL_GPIO_WritePin(RTS_GPIO_Port, RTS_Pin, GPIO_PIN_RESET);

  /*Configure GPIO pin : LTDC_DISP_Pin */
  GPIO_InitStruct.Pin = LTDC_DISP_Pin;
  GPIO_InitStruct.Mode = GPIO_MODE_OUTPUT_PP;
  GPIO_InitStruct.Pull = GPIO_NOPULL;
  GPIO_InitStruct.Speed = GPIO_SPEED_FREQ_LOW;
  HAL_GPIO_Init(LTDC_DISP_GPIO_Port, &GPIO_InitStruct);

  /*Configure GPIO pin : CTP_RST_Pin */
  GPIO_InitStruct.Pin = CTP_RST_Pin;
  GPIO_InitStruct.Mode = GPIO_MODE_OUTPUT_PP;
  GPIO_InitStruct.Pull = GPIO_NOPULL;
  GPIO_InitStruct.Speed = GPIO_SPEED_FREQ_LOW;
  HAL_GPIO_Init(CTP_RST_GPIO_Port, &GPIO_InitStruct);

  /*Configure GPIO pin : CTP_WAKE_Pin */
  GPIO_InitStruct.Pin = CTP_WAKE_Pin;
  GPIO_InitStruct.Mode = GPIO_MODE_OUTPUT_PP;
  GPIO_InitStruct.Pull = GPIO_NOPULL;
  GPIO_InitStruct.Speed = GPIO_SPEED_FREQ_LOW;
  HAL_GPIO_Init(CTP_WAKE_GPIO_Port, &GPIO_InitStruct);

  /*Configure GPIO pin : CTP_INT_Pin */
  GPIO_InitStruct.Pin = CTP_INT_Pin;
  GPIO_InitStruct.Mode = GPIO_MODE_IT_RISING;
  GPIO_InitStruct.Pull = GPIO_NOPULL;
  HAL_GPIO_Init(CTP_INT_GPIO_Port, &GPIO_InitStruct);

  /*Configure GPIO pin : GPIO_OUT_BEEP_Pin */
  GPIO_InitStruct.Pin = GPIO_OUT_BEEP_Pin;
  GPIO_InitStruct.Mode = GPIO_MODE_OUTPUT_PP;
  GPIO_InitStruct.Pull = GPIO_NOPULL;
  GPIO_InitStruct.Speed = GPIO_SPEED_FREQ_LOW;
  HAL_GPIO_Init(GPIO_OUT_BEEP_GPIO_Port, &GPIO_InitStruct);

  /*Configure GPIO pin : RTS_Pin */
  GPIO_InitStruct.Pin = RTS_Pin;
  GPIO_InitStruct.Mode = GPIO_MODE_OUTPUT_PP;
  GPIO_InitStruct.Pull = GPIO_NOPULL;
  GPIO_InitStruct.Speed = GPIO_SPEED_FREQ_LOW;
  HAL_GPIO_Init(RTS_GPIO_Port, &GPIO_InitStruct);

}

/* USER CODE BEGIN 4 */
void MX_SDRAM_InitEx(void)
{
  /* For SDRAM initial */
#define REFRESH_COUNT        1386                                     /*Todo check SDRAM clock*/
#define SDRAM_TIMEOUT                            ((uint32_t)0xFFFF)
#define SDRAM_MODEREG_BURST_LENGTH_1             ((uint16_t)0x0000)
#define SDRAM_MODEREG_BURST_LENGTH_2             ((uint16_t)0x0001)
#define SDRAM_MODEREG_BURST_LENGTH_4             ((uint16_t)0x0002)
#define SDRAM_MODEREG_BURST_LENGTH_8             ((uint16_t)0x0004)
#define SDRAM_MODEREG_BURST_TYPE_SEQUENTIAL      ((uint16_t)0x0000)
#define SDRAM_MODEREG_BURST_TYPE_INTERLEAVED     ((uint16_t)0x0008)
#define SDRAM_MODEREG_CAS_LATENCY_2              ((uint16_t)0x0020)
#define SDRAM_MODEREG_CAS_LATENCY_3              ((uint16_t)0x0030)
#define SDRAM_MODEREG_OPERATING_MODE_STANDARD    ((uint16_t)0x0000)
#define SDRAM_MODEREG_WRITEBURST_MODE_PROGRAMMED ((uint16_t)0x0000)
#define SDRAM_MODEREG_WRITEBURST_MODE_SINGLE     ((uint16_t)0x0200)

  __IO uint32_t tmpmrd = 0;
  FMC_SDRAM_CommandTypeDef Command;

  /* Step 1: Configure a clock configuration enable command */
  Command.CommandMode = FMC_SDRAM_CMD_CLK_ENABLE;
  Command.CommandTarget = FMC_SDRAM_CMD_TARGET_BANK2;
  Command.AutoRefreshNumber = 1;
  Command.ModeRegisterDefinition = 0;

  /* Send the command */
  HAL_SDRAM_SendCommand(&hsdram2, &Command, SDRAM_TIMEOUT);

  /* Step 2: Insert 100 us minimum delay */
  /* Inserted delay is equal to 1 ms due to systick time base unit (ms) */
  HAL_Delay(1);

  /* Step 3: Configure a PALL (precharge all) command */
  Command.CommandMode = FMC_SDRAM_CMD_PALL;
  Command.CommandTarget = FMC_SDRAM_CMD_TARGET_BANK2;
  Command.AutoRefreshNumber = 1;
  Command.ModeRegisterDefinition = 0;

  /* Send the command */
  HAL_SDRAM_SendCommand(&hsdram2, &Command, SDRAM_TIMEOUT);

  /* Step 4: Configure an Auto Refresh command */
  Command.CommandMode = FMC_SDRAM_CMD_AUTOREFRESH_MODE;
  Command.CommandTarget = FMC_SDRAM_CMD_TARGET_BANK2;
  Command.AutoRefreshNumber = 4;
  Command.ModeRegisterDefinition = 0;

  /* Send the command */
  HAL_SDRAM_SendCommand(&hsdram2, &Command, SDRAM_TIMEOUT);

  /* Step 5: Program the external memory mode register */
  /*Todo Check CAS_LATENCY value*/

  tmpmrd = (uint32_t) SDRAM_MODEREG_BURST_LENGTH_1
      |\
 SDRAM_MODEREG_BURST_TYPE_SEQUENTIAL |\
 SDRAM_MODEREG_CAS_LATENCY_3
      |\
 SDRAM_MODEREG_OPERATING_MODE_STANDARD
      |\
 SDRAM_MODEREG_WRITEBURST_MODE_SINGLE;

  Command.CommandMode = FMC_SDRAM_CMD_LOAD_MODE;
  Command.CommandTarget = FMC_SDRAM_CMD_TARGET_BANK2;
  Command.AutoRefreshNumber = 1;
  Command.ModeRegisterDefinition = tmpmrd;

  /* Send the command */
  HAL_SDRAM_SendCommand(&hsdram2, &Command, SDRAM_TIMEOUT);

  /* Step 6: Set the refresh rate counter */
  /* Set the device refresh rate */
  HAL_SDRAM_ProgramRefreshRate(&hsdram2, REFRESH_COUNT);
}

void HAL_CAN_RxFifo0MsgPendingCallback(CAN_HandleTypeDef *hcan)
{
	  CAN_RxHeaderTypeDef RxHeader;
	  Message rxMSG;
	  CAN_TxHeaderTypeDef TxHeader;
	  uint8_t TxData[8];
	  uint32_t TxMailbox;
	  // Get RX message and release fifo
	  if (HAL_CAN_GetRxMessage(hcan, CAN_RX_FIFO0, &RxHeader, rxMSG.data) != HAL_OK)
	    Error_Handler();

	  TxHeader.StdId = RxHeader.StdId;
	  TxHeader.ExtId = 0x00;
	  TxHeader.RTR = ( RxHeader.RTR == CAN_RTR_REMOTE ) ? 1 : 0;
	  TxHeader.IDE = CAN_ID_STD;
	  TxHeader.DLC = RxHeader.DLC;
	  TxHeader.TransmitGlobalTime = DISABLE;

	  for (uint8_t i = 0; i < 8; i++)
		  TxData[i] = rxMSG.data[i];

	  HAL_CAN_AddTxMessage(hcan, &TxHeader, TxData, &TxMailbox);
}

void HAL_CAN_RxFifo1MsgPendingCallback(CAN_HandleTypeDef *hcan)
{
	  CAN_RxHeaderTypeDef RxHeader;
	  Message rxMSG;
	  CAN_TxHeaderTypeDef TxHeader;
	  uint8_t TxData[8];
	  uint32_t TxMailbox;
	  // Get RX message and release fifo
	  if (HAL_CAN_GetRxMessage(hcan, CAN_RX_FIFO1, &RxHeader, rxMSG.data) != HAL_OK)
	    Error_Handler();

	  TxHeader.StdId = RxHeader.StdId;
	  TxHeader.ExtId = 0x00;
	  TxHeader.RTR = ( RxHeader.RTR == CAN_RTR_REMOTE ) ? 1 : 0;
	  TxHeader.IDE = CAN_ID_STD;
	  TxHeader.DLC = RxHeader.DLC;
	  TxHeader.TransmitGlobalTime = DISABLE;

	  for (uint8_t i = 0; i < 8; i++)
		  TxData[i] = rxMSG.data[i];

	  HAL_CAN_AddTxMessage(hcan, &TxHeader, TxData, &TxMailbox);
}

/* USER CODE END 4 */

void StartDefaultTask(void *argument)
{
  /* USER CODE BEGIN 5 */
	MX_TouchGFX_Process( );
  /* Infinite loop */
  for(;;)
  {
    osDelay(1);
  }
  /* USER CODE END 5 */
}

void StartModbusRTUTask(void *argument)
{
  for(;;)
  {
    osDelay(1);
  }
}

 /**
  * @brief  Period elapsed callback in non blocking mode
  * @note   This function is called  when TIM5 interrupt took place, inside
  * HAL_TIM_IRQHandler(). It makes a direct call to HAL_IncTick() to increment
  * a global variable "uwTick" used as application time base.
  * @param  htim : TIM handle
  * @retval None
  */
void HAL_TIM_PeriodElapsedCallback(TIM_HandleTypeDef *htim)
{
  if (htim->Instance == TIM5) {
    HAL_IncTick();
  }
}

void Error_Handler(void)
{
  __disable_irq();
  while (1)
  {
  }
}

/************************ (C) COPYRIGHT STMicroelectronics *****END OF FILE****/

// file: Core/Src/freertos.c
/* USER CODE BEGIN Header */
/**
  ******************************************************************************
  * File Name          : freertos.c
  * Description        : Code for freertos applications
  ******************************************************************************
  * @attention
  *
  * <h2><center>&copy; Copyright (c) 2022 STMicroelectronics.
  * All rights reserved.</center></h2>
  *
  * This software component is licensed by ST under Ultimate Liberty license
  * SLA0044, the "License"; You may not use this file except in compliance with
  * the License. You may obtain a copy of the License at:
  *                             www.st.com/SLA0044
  *
  ******************************************************************************
  */
/* USER CODE END Header */

#include "FreeRTOS.h"
#include "task.h"
#include "main.h"

/* Hook prototypes */
void vApplicationIdleHook(void);
void vApplicationTickHook(void);

/* USER CODE BEGIN 2 */
void vApplicationIdleHook( void )
{
   /* vApplicationIdleHook() will only be called if configUSE_IDLE_HOOK is set
   to 1 in FreeRTOSConfig.h. It will be called on each iteration of the idle
   task. It is essential that code added to this hook function never attempts
   to block in any way (for example, call xQueueReceive() with a block time
   specified, or call vTaskDelay()). If the application makes use of the
   vTaskDelete() API function (as this demo application does) then it is also
   important that vApplicationIdleHook() is permitted to return to its calling
   function, because it is the responsibility of the idle task to clean up
   memory allocated by the kernel to any task that has since been deleted. */
}
/* USER CODE END 2 */

/* USER CODE BEGIN 3 */
__weak void vApplicationTickHook( void )
{
   /* This function will be called by each tick interrupt if
   configUSE_TICK_HOOK is set to 1 in FreeRTOSConfig.h. User code can be
   added here, but the tick hook is called from an interrupt context, so
   code must not attempt to block, and only the interrupt safe FreeRTOS API
   functions can be used (those that end in FromISR()). */
}
/* USER CODE END 3 */

/************************ (C) COPYRIGHT STMicroelectronics *****END OF FILE****/
